VERSION ""

NS_ :

BS_:

BU_: ECU_3 ECU_2 ECU_1

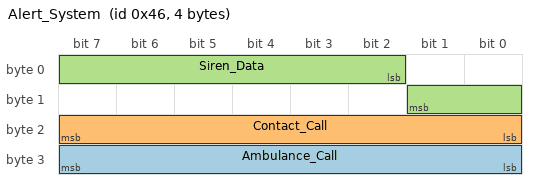
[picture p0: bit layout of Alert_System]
BO_ 70 Alert_System: 4 ECU_2
 SG_ Ambulance_Call : 24|8@1- (1,0) [0|0] "" Vector__XXX
 SG_ Contact_Call : 16|8@1- (1,0) [0|0] "" Vector__XXX
 SG_ Siren_Data : 2|8@1- (1,0) [0|0] "" Vector__XXX

BO_ 23 Force_Inp: 1 ECU_1
 SG_ Force_Data : 0|8@1- (1,0) [0|0] "Newton" Vector__XXX

BA_DEF_  "BusType" STRING ;
BA_DEF_DEF_  "BusType" "CAN";
